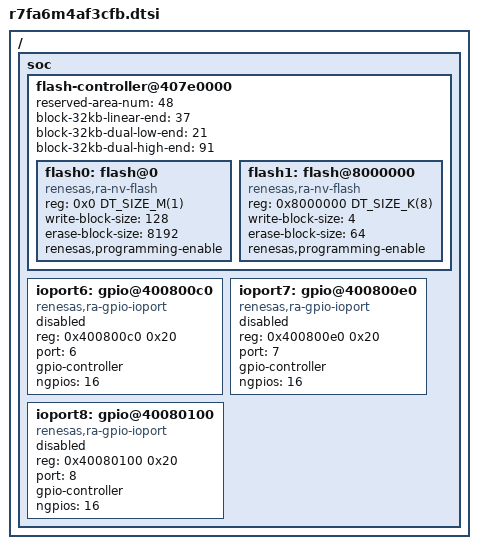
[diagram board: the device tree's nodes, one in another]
/*
 * Copyright (c) 2024 Renesas Electronics Corporation
 *
 * SPDX-License-Identifier: Apache-2.0
 */

#include <arm/renesas/ra/ra6/r7fa6m4ax.dtsi>

/ {
	soc {
		flash-controller@407e0000 {
			reserved-area-num = <48>;
			block-32kb-linear-end = <37>;
			block-32kb-dual-low-end = <21>;
			block-32kb-dual-high-end = <91>;
			flash0: flash@0 {
				compatible = "renesas,ra-nv-flash";
				reg = <0x0 DT_SIZE_M(1)>;
				write-block-size = <128>;
				erase-block-size = <8192>;
				renesas,programming-enable;
			};

			flash1: flash@8000000 {
				compatible = "renesas,ra-nv-flash";
				reg = <0x8000000 DT_SIZE_K(8)>;
				write-block-size = <4>;
				erase-block-size = <64>;
				renesas,programming-enable;
			};
		};

		ioport6: gpio@400800c0 {
			compatible = "renesas,ra-gpio-ioport";
			reg = <0x400800c0 0x20>;
			port = <6>;
			gpio-controller;
			#gpio-cells = <2>;
			ngpios = <16>;
			status = "disabled";
		};

		ioport7: gpio@400800e0 {
			compatible = "renesas,ra-gpio-ioport";
			reg = <0x400800e0 0x20>;
			port = <7>;
			gpio-controller;
			#gpio-cells = <2>;
			ngpios = <16>;
			status = "disabled";
		};

		ioport8: gpio@40080100 {
			compatible = "renesas,ra-gpio-ioport";
			reg = <0x40080100 0x20>;
			port = <8>;
			gpio-controller;
			#gpio-cells = <2>;
			ngpios = <16>;
			status = "disabled";
		};
	};
};
